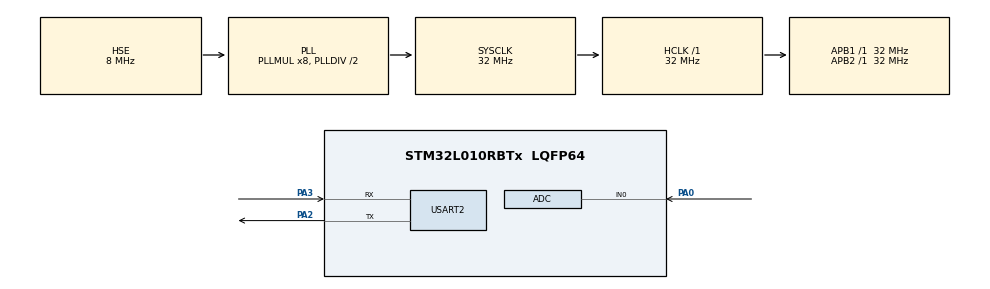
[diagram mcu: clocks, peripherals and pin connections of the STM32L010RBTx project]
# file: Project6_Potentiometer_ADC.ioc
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ADC.ContinuousConvMode=ENABLE
Mcu.Family=STM32L0
Mcu.Name=STM32L010RBTx
Mcu.Package=LQFP64
PA0.Mode=IN0
PA0.Signal=ADC_IN0
PA13.Mode=Serial_Wire
PA13.Signal=SYS_SWDIO
PA14.Mode=Serial_Wire
PA14.Signal=SYS_SWCLK
PA2.Mode=Asynchronous
PA2.Signal=USART2_TX
PA3.Mode=Asynchronous
PA3.Signal=USART2_RX
PH0-OSC_IN.Mode=HSE-External-Oscillator
PH0-OSC_IN.Signal=RCC_OSC_IN
PH1-OSC_OUT.Mode=HSE-External-Oscillator
PH1-OSC_OUT.Signal=RCC_OSC_OUT
ProjectManager.HeapSize=0x200
ProjectManager.StackSize=0x400
ProjectManager.TargetToolchain=EWARM V8.32
RCC.AHBFreq_Value=32000000
RCC.APB1Freq_Value=32000000
RCC.APB1TimFreq_Value=32000000
RCC.APB2Freq_Value=32000000
RCC.APB2TimFreq_Value=32000000
RCC.HCLKFreq_Value=32000000
RCC.HSE_VALUE=8000000
RCC.HSI16_VALUE=16000000
RCC.HSI48_VALUE=48000000
RCC.HSI_VALUE=16000000
RCC.LSEState=RCC_LSE_ON
RCC.LSE_VALUE=32768
RCC.MSI_VALUE=2097000
RCC.PLLMUL=RCC_PLLMUL_8
RCC.PLLSourceVirtual=RCC_PLLSOURCE_HSE
RCC.SYSCLKFreq_VALUE=32000000
RCC.SYSCLKSource=RCC_SYSCLKSOURCE_PLLCLK
RCC.VCOOutputFreq_Value=64000000
USART2.VirtualMode-Asynchronous=VM_ASYNC
board=NUCLEO-L010RB

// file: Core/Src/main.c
/* USER CODE BEGIN Header */
/**
  ******************************************************************************
  * @file           : main.c
  * @brief          : Main program body
  ******************************************************************************
  * @attention
  *
  * <h2><center>&copy; Copyright (c) 2021 STMicroelectronics.
  * All rights reserved.</center></h2>
  *
  * This software component is licensed by ST under BSD 3-Clause license,
  * the "License"; You may not use this file except in compliance with the
  * License. You may obtain a copy of the License at:
  *                        opensource.org/licenses/BSD-3-Clause
  *
  ******************************************************************************
  */
/* USER CODE END Header */
#include "main.h"

/* USER CODE BEGIN Includes */
#include <string.h>
#include <stdio.h>
/* USER CODE END Includes */

ADC_HandleTypeDef hadc;

UART_HandleTypeDef huart2;

void SystemClock_Config(void);
static void MX_GPIO_Init(void);
static void MX_ADC_Init(void);
static void MX_USART2_UART_Init(void);

int main(void)
{
  /* USER CODE BEGIN 1 */
uint16_t raw;
char msg[10];
  /* USER CODE END 1 */

  /* MCU Configuration--------------------------------------------------------*/

  /* Reset of all peripherals, Initializes the Flash interface and the Systick. */
  HAL_Init();

  /* Configure the system clock */
  SystemClock_Config();

  /* Initialize all configured peripherals */
  MX_GPIO_Init();
  MX_ADC_Init();
  MX_USART2_UART_Init();

  /* Infinite loop */
  while (1)
  {

    /* USER CODE BEGIN 3 */
    HAL_ADC_Start(&hadc);
    HAL_ADC_PollForConversion(&hadc, HAL_MAX_DELAY);
    raw = HAL_ADC_GetValue(&hadc);

    sprintf(msg, "Salutare prieteni %hu\r\n", raw);
    HAL_UART_Transmit(&huart2, (uint8_t*)msg, strlen(msg), HAL_MAX_DELAY);

    // Pretend we have to do something else for a while
    HAL_Delay(1000);
  }
  /* USER CODE END 3 */
}

void SystemClock_Config(void)
{
  RCC_OscInitTypeDef RCC_OscInitStruct = {0};
  RCC_ClkInitTypeDef RCC_ClkInitStruct = {0};
  RCC_PeriphCLKInitTypeDef PeriphClkInit = {0};

  /** Configure the main internal regulator output voltage
  */
  __HAL_PWR_VOLTAGESCALING_CONFIG(PWR_REGULATOR_VOLTAGE_SCALE1);
  /** Initializes the RCC Oscillators according to the specified parameters
  * in the RCC_OscInitTypeDef structure.
  */
  RCC_OscInitStruct.OscillatorType = RCC_OSCILLATORTYPE_HSE;
  RCC_OscInitStruct.HSEState = RCC_HSE_ON;
  RCC_OscInitStruct.PLL.PLLState = RCC_PLL_ON;
  RCC_OscInitStruct.PLL.PLLSource = RCC_PLLSOURCE_HSE;
  RCC_OscInitStruct.PLL.PLLMUL = RCC_PLLMUL_8;
  RCC_OscInitStruct.PLL.PLLDIV = RCC_PLLDIV_2;
  if (HAL_RCC_OscConfig(&RCC_OscInitStruct) != HAL_OK)
  {
    Error_Handler();
  }
  /** Initializes the CPU, AHB and APB buses clocks
  */
  RCC_ClkInitStruct.ClockType = RCC_CLOCKTYPE_HCLK|RCC_CLOCKTYPE_SYSCLK
                              |RCC_CLOCKTYPE_PCLK1|RCC_CLOCKTYPE_PCLK2;
  RCC_ClkInitStruct.SYSCLKSource = RCC_SYSCLKSOURCE_PLLCLK;
  RCC_ClkInitStruct.AHBCLKDivider = RCC_SYSCLK_DIV1;
  RCC_ClkInitStruct.APB1CLKDivider = RCC_HCLK_DIV1;
  RCC_ClkInitStruct.APB2CLKDivider = RCC_HCLK_DIV1;

  if (HAL_RCC_ClockConfig(&RCC_ClkInitStruct, FLASH_LATENCY_1) != HAL_OK)
  {
    Error_Handler();
  }
  PeriphClkInit.PeriphClockSelection = RCC_PERIPHCLK_USART2;
  PeriphClkInit.Usart2ClockSelection = RCC_USART2CLKSOURCE_PCLK1;
  if (HAL_RCCEx_PeriphCLKConfig(&PeriphClkInit) != HAL_OK)
  {
    Error_Handler();
  }
}

static void MX_ADC_Init(void)
{

  ADC_ChannelConfTypeDef sConfig = {0};

  /** Configure the global features of the ADC (Clock, Resolution, Data Alignment and number of conversion)
  */
  hadc.Instance = ADC1;
  hadc.Init.OversamplingMode = DISABLE;
  hadc.Init.ClockPrescaler = ADC_CLOCK_SYNC_PCLK_DIV2;
  hadc.Init.Resolution = ADC_RESOLUTION_12B;
  hadc.Init.SamplingTime = ADC_SAMPLETIME_1CYCLE_5;
  hadc.Init.ScanConvMode = ADC_SCAN_DIRECTION_FORWARD;
  hadc.Init.DataAlign = ADC_DATAALIGN_RIGHT;
  hadc.Init.ContinuousConvMode = ENABLE;
  hadc.Init.DiscontinuousConvMode = DISABLE;
  hadc.Init.ExternalTrigConvEdge = ADC_EXTERNALTRIGCONVEDGE_NONE;
  hadc.Init.ExternalTrigConv = ADC_SOFTWARE_START;
  hadc.Init.DMAContinuousRequests = DISABLE;
  hadc.Init.EOCSelection = ADC_EOC_SINGLE_CONV;
  hadc.Init.Overrun = ADC_OVR_DATA_PRESERVED;
  hadc.Init.LowPowerAutoWait = DISABLE;
  hadc.Init.LowPowerFrequencyMode = DISABLE;
  hadc.Init.LowPowerAutoPowerOff = DISABLE;
  if (HAL_ADC_Init(&hadc) != HAL_OK)
  {
    Error_Handler();
  }
  /** Configure for the selected ADC regular channel to be converted.
  */
  sConfig.Channel = ADC_CHANNEL_0;
  sConfig.Rank = ADC_RANK_CHANNEL_NUMBER;
  if (HAL_ADC_ConfigChannel(&hadc, &sConfig) != HAL_OK)
  {
    Error_Handler();
  }

}

static void MX_USART2_UART_Init(void)
{

  huart2.Instance = USART2;
  huart2.Init.BaudRate = 115200;
  huart2.Init.WordLength = UART_WORDLENGTH_8B;
  huart2.Init.StopBits = UART_STOPBITS_1;
  huart2.Init.Parity = UART_PARITY_NONE;
  huart2.Init.Mode = UART_MODE_TX_RX;
  huart2.Init.HwFlowCtl = UART_HWCONTROL_NONE;
  huart2.Init.OverSampling = UART_OVERSAMPLING_16;
  huart2.Init.OneBitSampling = UART_ONE_BIT_SAMPLE_DISABLE;
  huart2.AdvancedInit.AdvFeatureInit = UART_ADVFEATURE_NO_INIT;
  if (HAL_UART_Init(&huart2) != HAL_OK)
  {
    Error_Handler();
  }

}

static void MX_GPIO_Init(void)
{

  /* GPIO Ports Clock Enable */
  __HAL_RCC_GPIOH_CLK_ENABLE();
  __HAL_RCC_GPIOA_CLK_ENABLE();

}

void Error_Handler(void)
{
  __disable_irq();
  while (1)
  {
  }
}

/************************ (C) COPYRIGHT STMicroelectronics *****END OF FILE****/
